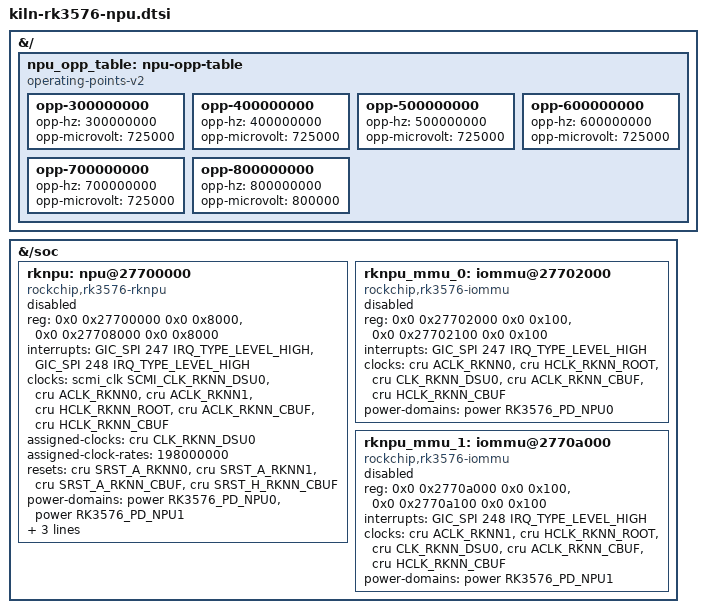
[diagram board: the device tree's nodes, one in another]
// SPDX-License-Identifier: (GPL-2.0-only OR MIT)
/*
 * Kiln: RK3576 NPU node for the out-of-tree vendor rknpu (v0.9.8) driver
 * on a MAINLINE kernel.
 *
 * IMPORTANT: these values are the GROUND TRUTH from the Rockchip BSP
 * (rockchip-linux/kernel develop-6.1, arch/arm64/boot/dts/rockchip/rk3576.dtsi
 * lines ~2512 and ~2748). They are NOT the guessed rocket addresses.
 *
 * The vendor rknpu driver binds compatible = "rockchip,rk3576-rknpu" and a
 * SINGLE npu node with two register banks (npu0/npu1) + a v2 IOMMU. Do not use
 * the RK3588-style 3-core (pc/cna/core) split here — that is a rocket-only
 * layout and the vendor driver will not bind to it.
 *
 * Include from your board DTS and enable:
 *     &rknpu       { status = "okay"; };
 *     &rknpu_mmu_0 { status = "okay"; };
 *     &rknpu_mmu_1 { status = "okay"; };
 *
 * BOARD-SPECIFIC (you must supply): npu-supply / sram-supply regulators.
 * On ROCK 4D these are the vdd_npu_s0 rail (see rk3576-rock-4d.dts). Add:
 *     &rknpu { npu-supply = <&vdd_npu_s0>; };
 */

#include <dt-bindings/clock/rockchip,rk3576-cru.h>
#include <dt-bindings/interrupt-controller/arm-gic.h>
#include <dt-bindings/interrupt-controller/irq.h>
#include <dt-bindings/power/rockchip,rk3576-power.h>
#include <dt-bindings/reset/rockchip,rk3576-cru.h>

/*
 * SCMI clock index for the NPU DSU clock.
 *
 * A reference through &scmi_clk passes this number to BL31 as the SCMI clock
 * id, so it must match the FIRMWARE's SCMI clock table index, NOT the mainline
 * CRU renumbering. In the mainline CRU header CLK_RKNN_DSU0 == 232, but BL31's
 * SCMI table registers the NPU clock at index 238 (TF-A rk3576_clk.h:246,
 * rk3576_clk.c:1101/1133). Mainline follows this convention for the clocks it
 * already exposes: SCMI_ARMCLK_L=10, SCMI_ARMCLK_B=11, SCMI_CLK_GPU=456 all
 * equal the firmware indices. Mainline has no SCMI_CLK_RKNN_DSU0 yet (no NPU
 * node upstream), so define it here. Using the plain CRU CLK_RKNN_DSU0 (232)
 * would address firmware index 232 (PCLK_WDT) and the NPU clock would never
 * come up.
 */
#define SCMI_CLK_RKNN_DSU0 238

&{/} {
	/*
	 * NPU OPP table.
	 *
	 * The vendor table reads PVTM/leakage nvmem cells for per-chip voltage
	 * selection. For bring-up this is a SIMPLIFIED fixed-rate table. Voltages
	 * are the vendor NOMINAL (target) values from the vendor npu_opp_table in
	 * rk3576.dtsi (300-700 MHz target = 725000, 800 MHz = 800000). Do NOT go
	 * below these: the earlier 675000/700000 rows were UNDER the vendor 725000
	 * floor and risk NPU instability. Once the efuse/nvmem nodes are wired,
	 * switch to the full vendor OPP with nvmem-cells = <&npu_leakage>,
	 * <&npu_opp_info>, ... for real PVTM/leakage-based DVFS.
	 */
	npu_opp_table: npu-opp-table {
		compatible = "operating-points-v2";

		opp-300000000 { opp-hz = /bits/ 64 <300000000>; opp-microvolt = <725000>; };
		opp-400000000 { opp-hz = /bits/ 64 <400000000>; opp-microvolt = <725000>; };
		opp-500000000 { opp-hz = /bits/ 64 <500000000>; opp-microvolt = <725000>; };
		opp-600000000 { opp-hz = /bits/ 64 <600000000>; opp-microvolt = <725000>; };
		opp-700000000 { opp-hz = /bits/ 64 <700000000>; opp-microvolt = <725000>; };
		opp-800000000 { opp-hz = /bits/ 64 <800000000>; opp-microvolt = <800000>; };
	};
};

&{/soc} {
	/*
	 * NPU (single node, two banks). GROUND TRUTH: rk3576.dtsi:2512
	 */
	rknpu: npu@27700000 {
		compatible = "rockchip,rk3576-rknpu";
		reg = <0x0 0x27700000 0x0 0x8000>,
		      <0x0 0x27708000 0x0 0x8000>;
		interrupts = <GIC_SPI 247 IRQ_TYPE_LEVEL_HIGH>,
			     <GIC_SPI 248 IRQ_TYPE_LEVEL_HIGH>;
		interrupt-names = "npu0_irq", "npu1_irq";
		/*
		 * clk_npu goes through SCMI (BL31) using the FIRMWARE index 238,
		 * not the mainline CRU CLK_RKNN_DSU0 (232). See SCMI_CLK_RKNN_DSU0
		 * define above. The remaining five are plain CRU gates.
		 */
		clocks = <&scmi_clk SCMI_CLK_RKNN_DSU0>, <&cru ACLK_RKNN0>,
			 <&cru ACLK_RKNN1>, <&cru HCLK_RKNN_ROOT>,
			 <&cru ACLK_RKNN_CBUF>, <&cru HCLK_RKNN_CBUF>;
		clock-names = "clk_npu", "aclk0", "aclk1", "hclk_root",
			      "aclk_cbuf", "hclk_cbuf";
		assigned-clocks = <&cru CLK_RKNN_DSU0>;
		assigned-clock-rates = <198000000>;
		resets = <&cru SRST_A_RKNN0>, <&cru SRST_A_RKNN1>,
			 <&cru SRST_A_RKNN_CBUF>, <&cru SRST_H_RKNN_CBUF>;
		reset-names = "srst_a0", "srst_a1",
			      "srst_a_cbuf", "srst_h_cbuf";
		power-domains = <&power RK3576_PD_NPU0>, <&power RK3576_PD_NPU1>;
		power-domain-names = "npu0", "npu1";
		operating-points-v2 = <&npu_opp_table>;
		/* Two IOMMU nodes, one per NPU core: each carries its own power-domain
		 * so the driver-core supplier-resume (pm_runtime_get_suppliers ->
		 * rk_iommu_resume) powers the NPU domain before touching MMU registers.
		 * A single 4-bank node spanning PD_NPU0+PD_NPU1 has no power-domain and
		 * async-SError-panics in rk_iommu_is_stall_active on modprobe. */
		iommus = <&rknpu_mmu_0>, <&rknpu_mmu_1>;
		#cooling-cells = <2>;
		dynamic-power-coefficient = <2570>;
		/* npu-supply = <&vdd_npu_s0>;  <-- add in board DTS */
		status = "disabled";
	};

	/*
	 * NPU v2 IOMMU. GROUND TRUTH addresses: rk3576.dtsi:2748.
	 *
	 * compatible is DELIBERATELY changed from the vendor string
	 * "rockchip,iommu-v2" to the mainline pair below. Mainline
	 * drivers/iommu/rockchip-iommu.c only matches "rockchip,iommu" (v1) and
	 * "rockchip,rk3568-iommu" (v2); it does NOT match "rockchip,iommu-v2".
	 * The v2 page-table format is byte-identical between the two (DTE/PTE
	 * v2 bit layout and DMA_BIT_MASK(40) match the vendor driver), so
	 * "rockchip,rk3568-iommu" gets the same v2 ops and binds on mainline.
	 * The rknpu driver's rknpu_iommu.c layers multi-domain IOVA management
	 * on top via generic iommu_* APIs; it does not need the vendor string.
	 * This matches how mainline's own rk3576 MMU nodes are declared
	 * (rk3576.dtsi vop_mmu/vdec_mmu: "rockchip,rk3576-iommu","rockchip,rk3568-iommu").
	 */
	rknpu_mmu_0: iommu@27702000 {
		compatible = "rockchip,rk3576-iommu", "rockchip,rk3568-iommu";
		reg = <0x0 0x27702000 0x0 0x100>,
		      <0x0 0x27702100 0x0 0x100>;
		interrupts = <GIC_SPI 247 IRQ_TYPE_LEVEL_HIGH>;
		clocks = <&cru ACLK_RKNN0>, <&cru HCLK_RKNN_ROOT>,
			 <&cru CLK_RKNN_DSU0>, <&cru ACLK_RKNN_CBUF>,
			 <&cru HCLK_RKNN_CBUF>;
		#iommu-cells = <0>;
		power-domains = <&power RK3576_PD_NPU0>;
		status = "disabled";
	};

	rknpu_mmu_1: iommu@2770a000 {
		compatible = "rockchip,rk3576-iommu", "rockchip,rk3568-iommu";
		reg = <0x0 0x2770a000 0x0 0x100>,
		      <0x0 0x2770a100 0x0 0x100>;
		interrupts = <GIC_SPI 248 IRQ_TYPE_LEVEL_HIGH>;
		clocks = <&cru ACLK_RKNN1>, <&cru HCLK_RKNN_ROOT>,
			 <&cru CLK_RKNN_DSU0>, <&cru ACLK_RKNN_CBUF>,
			 <&cru HCLK_RKNN_CBUF>;
		#iommu-cells = <0>;
		power-domains = <&power RK3576_PD_NPU1>;
		status = "disabled";
	};
};
